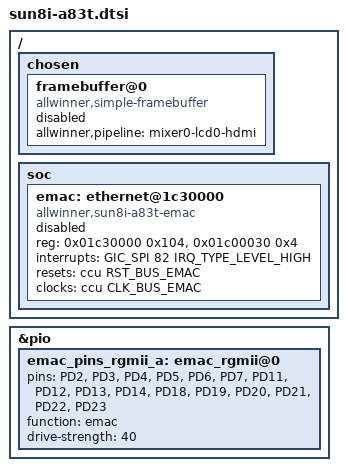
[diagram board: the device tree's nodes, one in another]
/* $NetBSD: sun8i-a83t.dtsi,v 1.1.2.2 2017/12/03 11:35:52 jdolecek Exp $ */

/*-
 * Copyright (c) 2017 Jared McNeill <jmcneill@invisible.ca>
 * All rights reserved.
 *
 * Redistribution and use in source and binary forms, with or without
 * modification, are permitted provided that the following conditions
 * are met:
 * 1. Redistributions of source code must retain the above copyright
 *    notice, this list of conditions and the following disclaimer.
 * 2. Redistributions in binary form must reproduce the above copyright
 *    notice, this list of conditions and the following disclaimer in the
 *    documentation and/or other materials provided with the distribution.
 *
 * THIS SOFTWARE IS PROVIDED BY THE AUTHOR ``AS IS'' AND ANY EXPRESS OR
 * IMPLIED WARRANTIES, INCLUDING, BUT NOT LIMITED TO, THE IMPLIED WARRANTIES
 * OF MERCHANTABILITY AND FITNESS FOR A PARTICULAR PURPOSE ARE DISCLAIMED.
 * IN NO EVENT SHALL THE AUTHOR BE LIABLE FOR ANY DIRECT, INDIRECT,
 * INCIDENTAL, SPECIAL, EXEMPLARY, OR CONSEQUENTIAL DAMAGES (INCLUDING,
 * BUT NOT LIMITED TO, PROCUREMENT OF SUBSTITUTE GOODS OR SERVICES;
 * LOSS OF USE, DATA, OR PROFITS; OR BUSINESS INTERRUPTION) HOWEVER CAUSED
 * AND ON ANY THEORY OF LIABILITY, WHETHER IN CONTRACT, STRICT LIABILITY,
 * OR TORT (INCLUDING NEGLIGENCE OR OTHERWISE) ARISING IN ANY WAY
 * OUT OF THE USE OF THIS SOFTWARE, EVEN IF ADVISED OF THE POSSIBILITY OF
 * SUCH DAMAGE.
 */

/ {
	chosen {
		#address-cells = <1>;
		#size-cells = <1>;
		ranges;

		framebuffer@0 {
			compatible = "allwinner,simple-framebuffer",
				     "simple-framebuffer";
			allwinner,pipeline = "mixer0-lcd0-hdmi";
			status = "disabled";
		};
	};

	soc {
		emac: ethernet@1c30000 {
			compatible = "allwinner,sun8i-a83t-emac";
			reg = <0x01c30000 0x104>, <0x01c00030 0x4>;
			reg-names = "emac", "syscon";
			interrupts = <GIC_SPI 82 IRQ_TYPE_LEVEL_HIGH>;
			resets = <&ccu RST_BUS_EMAC>;
			reset-names = "ahb";
			clocks = <&ccu CLK_BUS_EMAC>;
			clock-names = "ahb";
			#address-cells = <1>;
			#size-cells = <0>;
			status = "disabled";
		};
	};
};

&pio {
	emac_pins_rgmii_a: emac_rgmii@0 {
		pins = "PD2", "PD3", "PD4", "PD5", "PD6", "PD7",
		       "PD11", "PD12", "PD13", "PD14",
		       "PD18", "PD19", "PD20", "PD21", "PD22", "PD23";
		function = "emac";
		drive-strength = <40>;
	};
};
